# PIC32MK1024MCF100 register map
Vendor: Microchip
Registers are 32-bit, read-write, reset 0x0 unless marked. A register's access mark holds for its fields unless they carry their own. Addresses are absolute, and some are shared; only a register's first bit layout is shown; [hi:lo] are bit positions; {n}, {i} and the like mark numbered series; 'fields as' and 'values as' point back to an identical list.

## CAN4
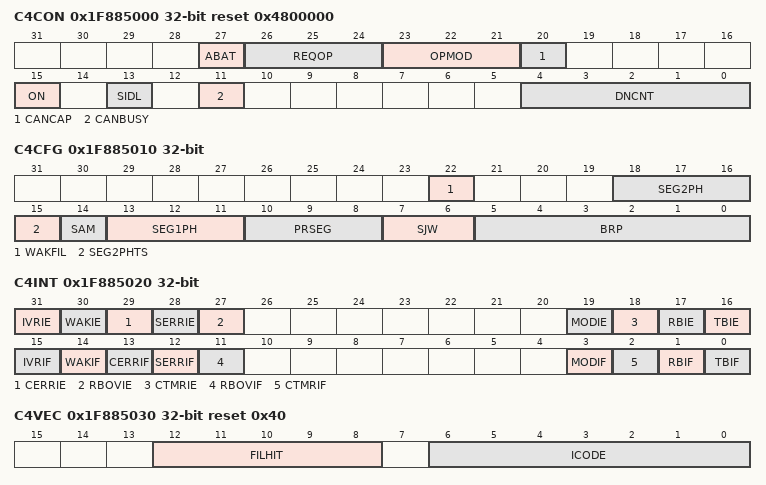
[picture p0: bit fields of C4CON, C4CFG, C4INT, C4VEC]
0x1F885000 C4CON reset 0x4800000
  [27] ABAT — (can only be set)
  [26:24] REQOP
  [23:21] OPMOD ro
  [20] CANCAP
  [15] ON
  [13] SIDL
  [11] CANBUSY ro
  [4:0] DNCNT
0x1F885010 C4CFG
  [22] WAKFIL, [18:16] SEG2PH, [15] SEG2PHTS, [14] SAM, [13:11] SEG1PH, [10:8] PRSEG, [7:6] SJW, [5:0] BRP
0x1F885020 C4INT
  [31] IVRIE, [30] WAKIE, [29] CERRIE, [28] SERRIE, [27] RBOVIE, [19] MODIE, [18] CTMRIE, [17] RBIE, [16] TBIE, [15] IVRIF, [14] WAKIF, [13] CERRIF, [12] SERRIF, [11] RBOVIF, [3] MODIF, [2] CTMRIF, [1] RBIF, [0] TBIF
0x1F885030 C4VEC ro reset 0x40
  [12:8] FILHIT, [6:0] ICODE
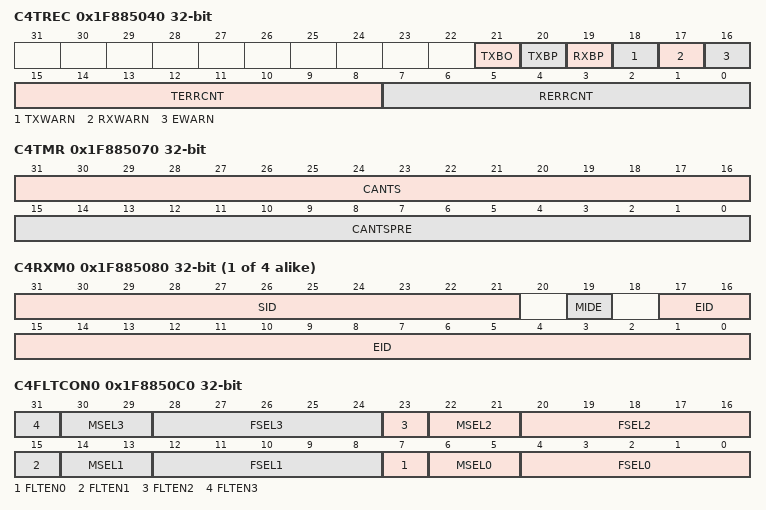
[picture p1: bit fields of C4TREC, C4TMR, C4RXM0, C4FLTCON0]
0x1F885040 C4TREC ro
  [21] TXBO, [20] TXBP, [19] RXBP, [18] TXWARN, [17] RXWARN, [16] EWARN, [15:8] TERRCNT, [7:0] RERRCNT
0x1F885050 C4FSTAT ro
  [15:0] FIFOIP
0x1F885060 C4RXOVF ro
  [15:0] RXOVF
0x1F885070 C4TMR
  [31:16] CANTS, [15:0] CANTSPRE
{0x1F885080+0x10*i} C4RXM{i} (i=0..3)
  [31:21] SID, [19] MIDE, [17:0] EID
0x1F8850C0 C4FLTCON0
  [8n+7] FLTEN{n} (n=0..3), [8n+6:8n+5] MSEL{n} (n=0..3), [8n+4:8n] FSEL{n} (n=0..3)
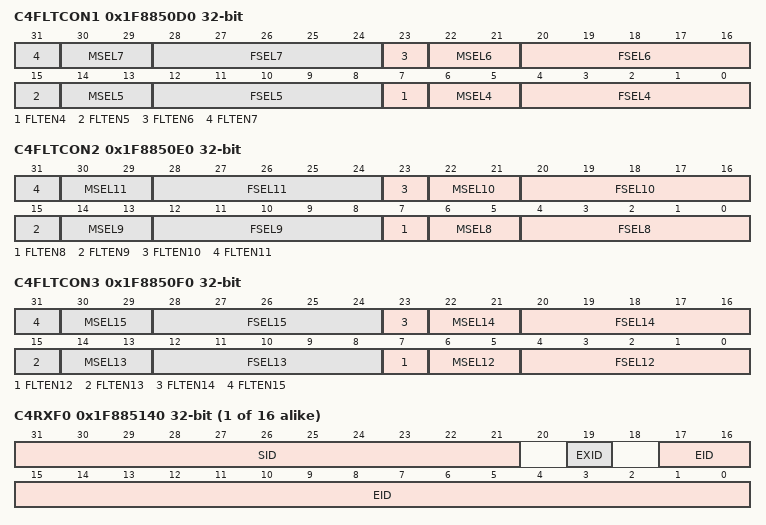
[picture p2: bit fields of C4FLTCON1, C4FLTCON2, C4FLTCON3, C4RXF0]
0x1F8850D0 C4FLTCON1
  [8n-25] FLTEN{n} (n=4..7), [8n-26:8n-27] MSEL{n} (n=4..7), [8n-28:8n-32] FSEL{n} (n=4..7)
0x1F8850E0 C4FLTCON2
  [8n-57] FLTEN{n} (n=8..11), [8n-58:8n-59] MSEL{n} (n=8..11), [8n-60:8n-64] FSEL{n} (n=8..11)
0x1F8850F0 C4FLTCON3
  [8n-89] FLTEN{n} (n=12..15), [8n-90:8n-91] MSEL{n} (n=12..15), [8n-92:8n-96] FSEL{n} (n=12..15)
{0x1F885140+0x10*i} C4RXF{i} reset not defined (i=0..15) — (power-on value xxxxxxxxxxx0x0xxxxxxxxxxxxxxxxxx)
  [31:21] SID, [19] EXID, [17:0] EID
0x1F885340 C4FIFOBA
  [31:2] FIFOBA
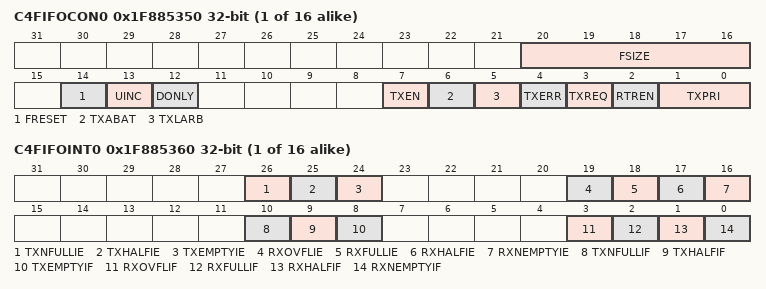
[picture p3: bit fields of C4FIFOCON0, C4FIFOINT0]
{0x1F885350+0x40*i} C4FIFOCON{i} (i=0..15)
  [20:16] FSIZE, [14] FRESET, [13] UINC, [12] DONLY, [7] TXEN, [6] TXABAT, [5] TXLARB, [4] TXERR, [3] TXREQ, [2] RTREN, [1:0] TXPRI
{0x1F885360+0x40*i} C4FIFOINT{i} (i=0..15)
  [26] TXNFULLIE, [25] TXHALFIE, [24] TXEMPTYIE, [19] RXOVFLIE, [18] RXFULLIE, [17] RXHALFIE, [16] RXNEMPTYIE, [10] TXNFULLIF ro, [9] TXHALFIF ro, [8] TXEMPTYIF ro, [3] RXOVFLIF, [2] RXFULLIF ro, [1] RXHALFIF ro, [0] RXNEMPTYIF ro
{0x1F885370+0x40*i} C4FIFOUA{i} ro reset not defined (i=0..15) — (power-on value xxxxxxxxxxxxxxxxxxxxxxxxxxxxxx00)
  [31:2] FIFOUA
{0x1F885380+0x40*i} C4FIFOCI{i} ro (i=0..15)
  [4:0] CFIFOCI

## adc_sar_ctrl_upb
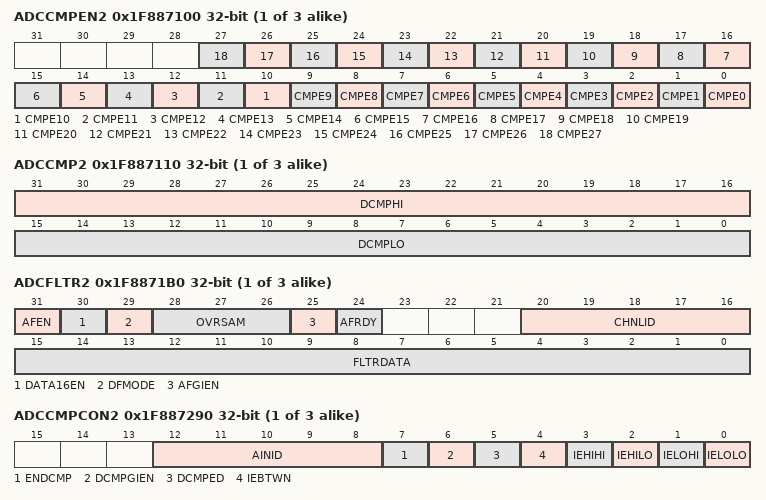
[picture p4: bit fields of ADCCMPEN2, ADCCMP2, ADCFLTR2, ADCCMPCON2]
{0x1F8870C0+0x20*i} ADCCMPEN{i} (i=2..4)
  [n] CMPE{n} (n=0..27)
{0x1F8870D0+0x20*i} ADCCMP{i} (i=2..4)
  [31:16] DCMPHI, [15:0] DCMPLO
{0x1F887190+0x10*i} ADCFLTR{i} (i=2..4)
  [31] AFEN, [30] DATA16EN, [29] DFMODE, [28:26] OVRSAM, [25] AFGIEN, [24] AFRDY ro, [20:16] CHNLID, [15:0] FLTRDATA ro
{0x1F887270+0x10*i} ADCCMPCON{i} (i=2..4)
  [12:8] AINID ro, [7] ENDCMP, [6] DCMPGIEN, [5] DCMPED ro, [4] IEBTWN, [3] IEHIHI, [2] IEHILO, [1] IELOHI, [0] IELOLO
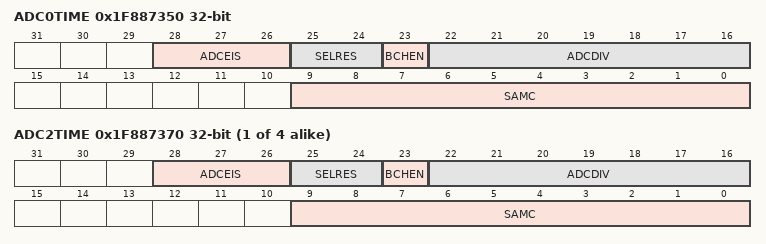
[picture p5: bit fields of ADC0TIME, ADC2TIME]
0x1F887350 ADC0TIME reset not defined — (power-on value ---00000x0000000------0000000000)
  [28:26] ADCEIS, [25:24] SELRES, [23] BCHEN, [22:16] ADCDIV, [9:0] SAMC
{0x1F887350+0x10*i} ADC{i}TIME reset not defined (i=2..5) — (power-on value ---00000x0000000------0000000000)
  fields as ADC0TIME

## USB1
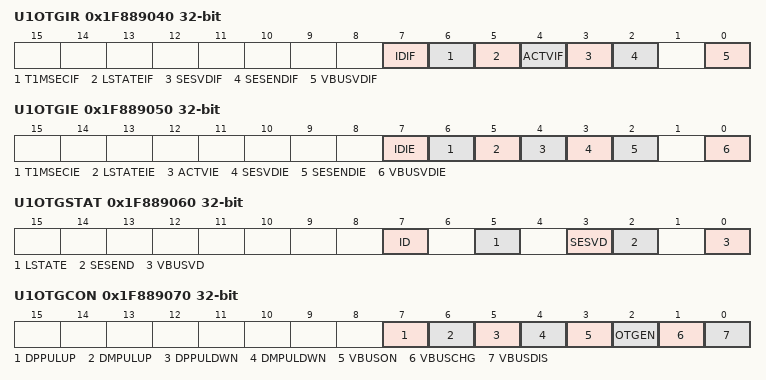
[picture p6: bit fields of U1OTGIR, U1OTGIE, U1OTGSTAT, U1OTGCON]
0x1F889040 U1OTGIR
  [7] IDIF, [6] T1MSECIF, [5] LSTATEIF, [4] ACTVIF, [3] SESVDIF, [2] SESENDIF, [0] VBUSVDIF
0x1F889050 U1OTGIE
  [7] IDIE, [6] T1MSECIE, [5] LSTATEIE, [4] ACTVIE, [3] SESVDIE, [2] SESENDIE, [0] VBUSVDIE
0x1F889060 U1OTGSTAT
  [7] ID, [5] LSTATE, [3] SESVD, [2] SESEND, [0] VBUSVD
0x1F889070 U1OTGCON
  [7] DPPULUP, [6] DMPULUP, [5] DPPULDWN, [4] DMPULDWN, [3] VBUSON, [2] OTGEN, [1] VBUSCHG, [0] VBUSDIS
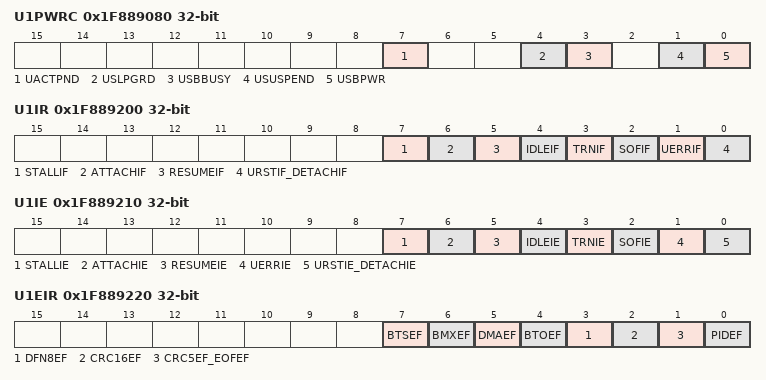
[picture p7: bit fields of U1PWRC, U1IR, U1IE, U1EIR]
0x1F889080 U1PWRC reset not defined — (power-on value ------------------------0--0x-00)
  [7] UACTPND ro, [4] USLPGRD, [3] USBBUSY, [1] USUSPEND, [0] USBPWR
0x1F889200 U1IR
  [7] STALLIF, [6] ATTACHIF, [5] RESUMEIF, [4] IDLEIF, [3] TRNIF, [2] SOFIF, [1] UERRIF, [0] URSTIF_DETACHIF
0x1F889210 U1IE
  [7] STALLIE, [6] ATTACHIE, [5] RESUMEIE, [4] IDLEIE, [3] TRNIE, [2] SOFIE, [1] UERRIE, [0] URSTIE_DETACHIE
0x1F889220 U1EIR
  [7] BTSEF, [6] BMXEF, [5] DMAEF, [4] BTOEF, [3] DFN8EF, [2] CRC16EF, [1] CRC5EF_EOFEF, [0] PIDEF
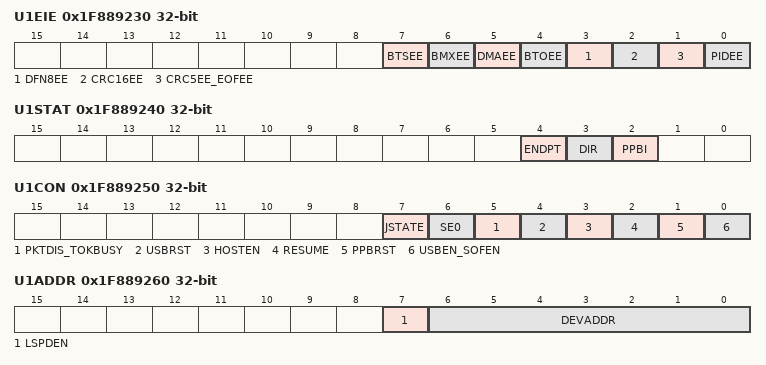
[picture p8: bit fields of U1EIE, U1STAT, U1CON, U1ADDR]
0x1F889230 U1EIE reset not defined — (power-on value ------------------------0000000x)
  [7] BTSEE, [6] BMXEE, [5] DMAEE, [4] BTOEE, [3] DFN8EE, [2] CRC16EE, [1] CRC5EE_EOFEE, [0] PIDEE
0x1F889240 U1STAT ro reset not defined
  [4] ENDPT, [3] DIR, [2] PPBI
0x1F889250 U1CON
  [7] JSTATE, [6] SE0, [5] PKTDIS_TOKBUSY, [4] USBRST, [3] HOSTEN, [2] RESUME, [1] PPBRST, [0] USBEN_SOFEN
0x1F889260 U1ADDR
  [7] LSPDEN, [6:0] DEVADDR
0x1F889270 U1BDTP1
  [7:1] BDTPTRL
0x1F889280 U1FRML ro reset not defined
  [7:0] FRML
0x1F889290 U1FRMH ro reset not defined
  [2:0] FRMH
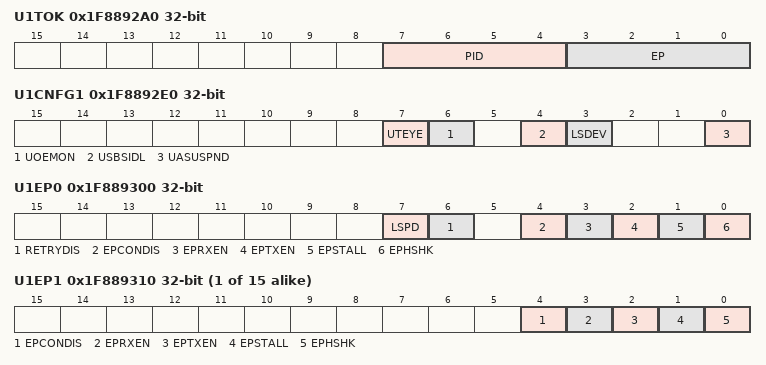
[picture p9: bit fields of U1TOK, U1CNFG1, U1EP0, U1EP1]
0x1F8892A0 U1TOK
  [7:4] PID, [3:0] EP
0x1F8892B0 U1SOF
  [7:0] CNT
0x1F8892C0 U1BDTP2
  [7:0] BDTPTRH
0x1F8892D0 U1BDTP3
  [7:0] BDTPTRU
0x1F8892E0 U1CNFG1 reset not defined — (power-on value ------------------------xxxxx00x)
  [7] UTEYE, [6] UOEMON, [4] USBSIDL, [3] LSDEV, [0] UASUSPND
0x1F889300 U1EP0
  [7] LSPD, [6] RETRYDIS, [4] EPCONDIS, [3] EPRXEN, [2] EPTXEN, [1] EPSTALL, [0] EPHSHK
{0x1F889300+0x10*i} U1EP{i} (i=1..15)
  [4] EPCONDIS, [3] EPRXEN, [2] EPTXEN, [1] EPSTALL, [0] EPHSHK
